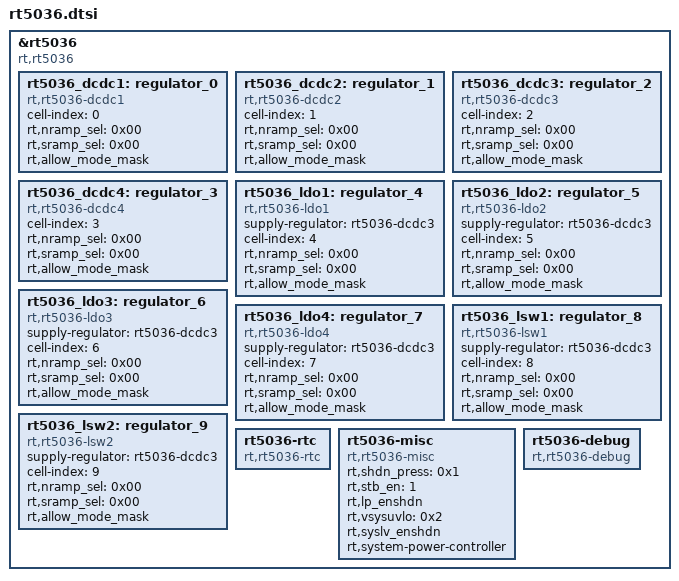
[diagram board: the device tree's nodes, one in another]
/* Copyright (c) 2014, The Linux Foundation. All rights reserved.
 *
 * This program is free software; you can redistribute it and/or modify
 * it under the terms of the GNU General Public License version 2 and
 * only version 2 as published by the Free Software Foundation.
 *
 * This program is distributed in the hope that it will be useful,
 * but WITHOUT ANY WARRANTY; without even the implied warranty of
 * MERCHANTABILITY or FITNESS FOR A PARTICULAR PURPOSE.  See the
 * GNU General Public License for more details.
 */

&rt5036 {
	compatible = "rt,rt5036";

			rt5036_dcdc1: regulator_0 {
				compatible = "rt,rt5036-dcdc1";
				cell-index = <0>;
				rt,nramp_sel = <0x00>;
				rt,sramp_sel = <0x00>;
				rt,allow_mode_mask;
			};
			rt5036_dcdc2: regulator_1 {
				compatible = "rt,rt5036-dcdc2";
				cell-index = <1>;
				rt,nramp_sel = <0x00>;
				rt,sramp_sel = <0x00>;
				rt,allow_mode_mask;
			};
			rt5036_dcdc3: regulator_2 {
				compatible = "rt,rt5036-dcdc3";
				cell-index = <2>;
				rt,nramp_sel = <0x00>;
				rt,sramp_sel = <0x00>;
				rt,allow_mode_mask;
			};
			rt5036_dcdc4: regulator_3 {
				compatible = "rt,rt5036-dcdc4";
				cell-index = <3>;
				rt,nramp_sel = <0x00>;
				rt,sramp_sel = <0x00>;
				rt,allow_mode_mask;
			};
			rt5036_ldo1: regulator_4 {
				supply-regulator = "rt5036-dcdc3";
				compatible = "rt,rt5036-ldo1";
				cell-index = <4>;
				rt,nramp_sel = <0x00>;
				rt,sramp_sel = <0x00>;
				rt,allow_mode_mask;
			};
			rt5036_ldo2: regulator_5 {
				supply-regulator = "rt5036-dcdc3";
				compatible = "rt,rt5036-ldo2";
				cell-index = <5>;
				rt,nramp_sel = <0x00>;
				rt,sramp_sel = <0x00>;
				rt,allow_mode_mask;
			};
			rt5036_ldo3: regulator_6 {
				supply-regulator = "rt5036-dcdc3";
				compatible = "rt,rt5036-ldo3";
				cell-index = <6>;
				rt,nramp_sel = <0x00>;
				rt,sramp_sel = <0x00>;
				rt,allow_mode_mask;
			};
			rt5036_ldo4: regulator_7 {
				supply-regulator = "rt5036-dcdc3";
				compatible = "rt,rt5036-ldo4";
				cell-index = <7>;
				rt,nramp_sel = <0x00>;
				rt,sramp_sel = <0x00>;
				rt,allow_mode_mask;
			};
			rt5036_lsw1: regulator_8 {
				supply-regulator = "rt5036-dcdc3";
				compatible = "rt,rt5036-lsw1";
				cell-index = <8>;
				rt,nramp_sel = <0x00>;
				rt,sramp_sel = <0x00>;
				rt,allow_mode_mask;
			};
			rt5036_lsw2: regulator_9 {
				supply-regulator = "rt5036-dcdc3";
				compatible = "rt,rt5036-lsw2";
				cell-index = <9>;
				rt,nramp_sel = <0x00>;
				rt,sramp_sel = <0x00>;
				rt,allow_mode_mask;
			};
			rt5036-rtc {
				compatible = "rt,rt5036-rtc";
			};
			rt5036-misc {
				compatible = "rt,rt5036-misc";
				rt,shdn_press = <0x1>;
				rt,stb_en = <1>;
				rt,lp_enshdn;
				rt,vsysuvlo = <0x2>;
				rt,syslv_enshdn;
				rt,system-power-controller;
			};
			rt5036-debug {
				compatible = "rt,rt5036-debug";
			};
	};

